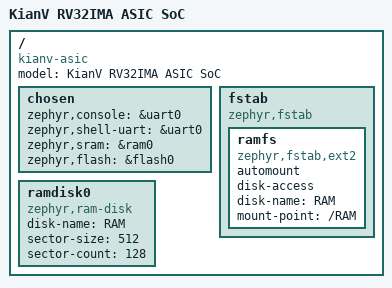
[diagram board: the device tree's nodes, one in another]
// SPDX-License-Identifier: Apache-2.0
/* Copyright (c) 2026 Hirosh Dabui <hirosh@dabui.de> */

/dts-v1/;

#include <kianv/kianv_rv32ima.dtsi>

/ {
	model = "KianV RV32IMA ASIC SoC";
	compatible = "kianv-asic";

	chosen {
		zephyr,console = &uart0;
		zephyr,shell-uart = &uart0;
		zephyr,sram = &ram0;
		zephyr,flash = &flash0;
	};

	fstab {
		compatible = "zephyr,fstab";

		ramfs: ramfs {
			compatible = "zephyr,fstab,ext2";
			automount;
			disk-access;
			disk-name = "RAM";
			mount-point = "/RAM";
		};
	};

	ramdisk0 {
		compatible = "zephyr,ram-disk";
		disk-name = "RAM";
		sector-size = <512>;
		sector-count = <128>;
	};
};
